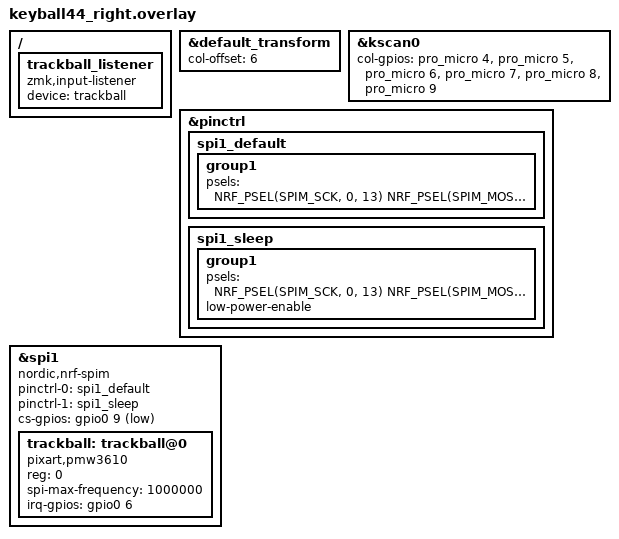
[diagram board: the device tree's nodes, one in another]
/*
 * SPDX-License-Identifier: MIT
 */

#include "keyball44.dtsi"

/* =============================
 * 右手側のキー配列設定
 * ============================= */
&default_transform {
    col-offset = <6>;
};

&kscan0 {
    col-gpios
        = <&pro_micro 4 GPIO_ACTIVE_HIGH>
        , <&pro_micro 5 GPIO_ACTIVE_HIGH>
        , <&pro_micro 6 GPIO_ACTIVE_HIGH>
        , <&pro_micro 7 GPIO_ACTIVE_HIGH>
        , <&pro_micro 8 GPIO_ACTIVE_HIGH>
        , <&pro_micro 9 GPIO_ACTIVE_HIGH>
        ;
};

/* =========================================================
 * Trackball (PMW3360) : 右側のみ
 *  - spi1 を使用（i2c0 / spi0 と競合させない）
 * ========================================================= */

/* ---------- SPI1 pinctrl ---------- */
&pinctrl {
    spi1_default: spi1_default {
        group1 {
            psels = <
                NRF_PSEL(SPIM_SCK,  0, 13)   /* SCK */
                NRF_PSEL(SPIM_MOSI, 0, 15)   /* MOSI */
                NRF_PSEL(SPIM_MISO, 0, 14)   /* MISO */
            >;
        };
    };

    spi1_sleep: spi1_sleep {
        group1 {
            psels = <
                NRF_PSEL(SPIM_SCK,  0, 13)
                NRF_PSEL(SPIM_MOSI, 0, 15)
                NRF_PSEL(SPIM_MISO, 0, 14)
            >;
            low-power-enable;
        };
    };
};

/* ---------- SPI1 本体 ---------- */
&spi1 {
    status = "okay";
    compatible = "nordic,nrf-spim";

    pinctrl-0 = <&spi1_default>;
    pinctrl-1 = <&spi1_sleep>;
    pinctrl-names = "default", "sleep";

    /* CS ピン */
    cs-gpios = <&gpio0 9 GPIO_ACTIVE_LOW>;

    trackball: trackball@0 {
        status = "okay";
        compatible = "pixart,pmw3610";
        reg = <0>;

        /* 最初は低速で安定させる */
        spi-max-frequency = <1000000>;

        /* IRQ */
       irq-gpios = <&gpio0 6 (GPIO_ACTIVE_HIGH | GPIO_PULL_DOWN)>;
    };
};

/* ---------- ZMK に入力を流す ---------- */
 / {
    trackball_listener {
        compatible = "zmk,input-listener";
        device = <&trackball>;
    };
};
